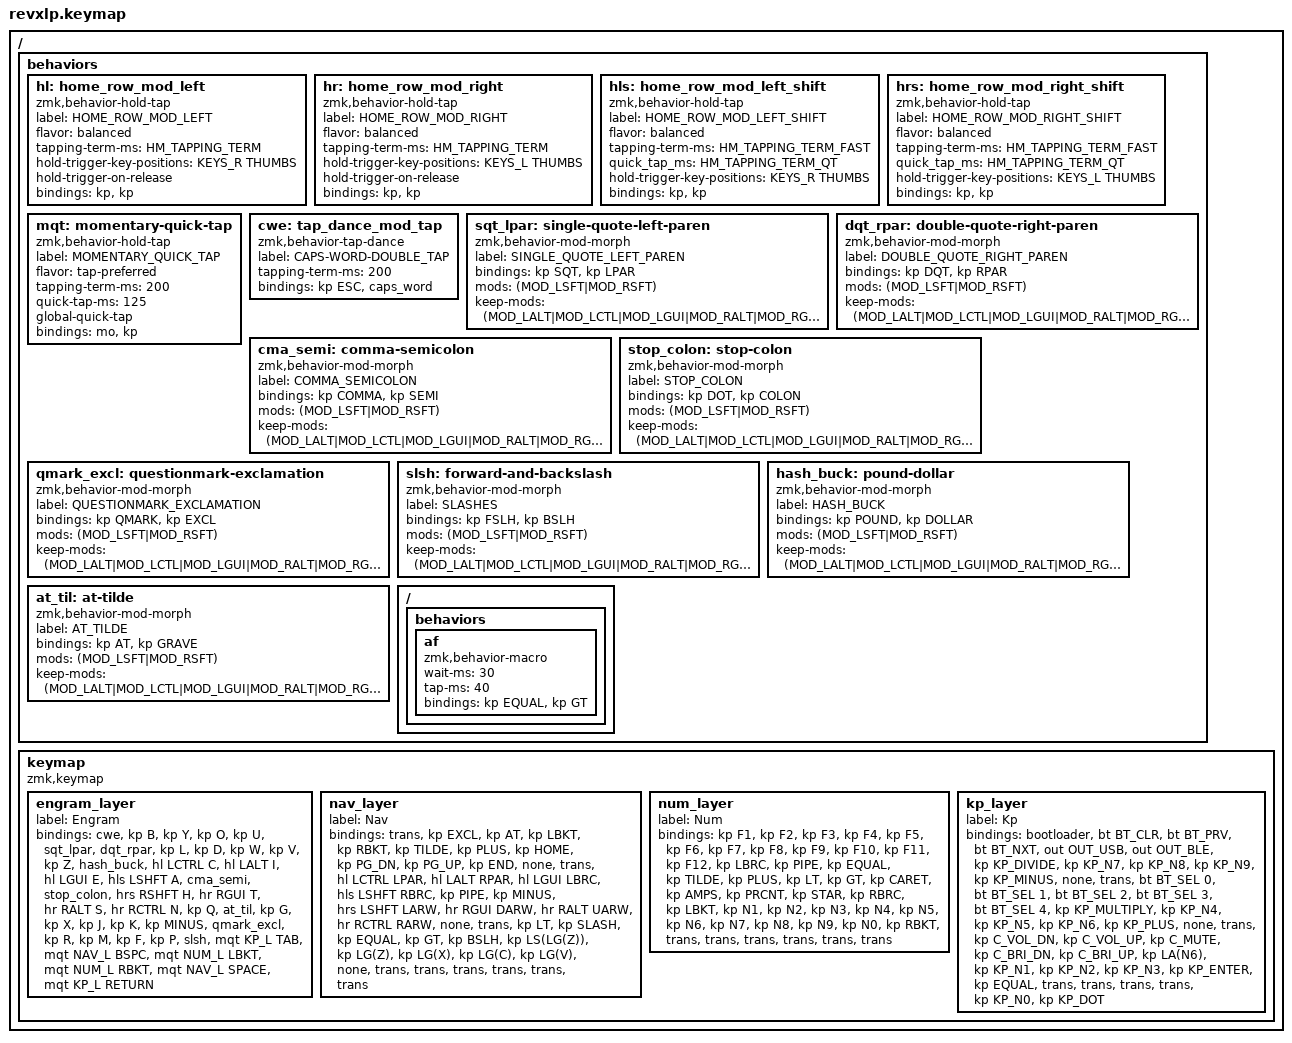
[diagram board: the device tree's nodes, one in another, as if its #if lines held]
/*
* Copyright (c) 2020 The ZMK Contributors
*
* SPDX-License-Identifier: MIT
*/

#include <behaviors.dtsi>
#include <dt-bindings/zmk/keys.h>
#include <dt-bindings/zmk/bt.h>
#include <dt-bindings/zmk/backlight.h>
#include <dt-bindings/zmk/outputs.h>

#define NAV_L 1
#define NUM_L 2
#define KP_L 3

#define KEYS_L 0 1 2 3 4  5  12 13 14 15 16 17 24 25 26 27 28 29// left-hand keys
#define KEYS_R 6 7 8 9 10 11 18 19 20 21 22 23 30 31 32 33 34 35// right-hand keys
#define THUMBS 36 37 38 39 40 41

#define HM_TAPPING_TERM 1000
#define HM_TAPPING_TERM_FAST 200
#define HM_TAPPING_TERM_QT 175

/ {
	behaviors {
		
		hl: home_row_mod_left {
			compatible = "zmk,behavior-hold-tap";
			label = "HOME_ROW_MOD_LEFT";
			#binding-cells = <2>;
			flavor = "balanced";
			tapping-term-ms = <HM_TAPPING_TERM>;
			hold-trigger-key-positions = < KEYS_R THUMBS >;
			hold-trigger-on-release;
			bindings = <&kp>, <&kp>;
		};
		
		hr: home_row_mod_right {
			compatible = "zmk,behavior-hold-tap";
			label = "HOME_ROW_MOD_RIGHT";
			#binding-cells = <2>;
			flavor = "balanced";
			tapping-term-ms = <HM_TAPPING_TERM>;
			hold-trigger-key-positions = < KEYS_L THUMBS >;
			hold-trigger-on-release;
			bindings = <&kp>, <&kp>;
		};
		
		hls: home_row_mod_left_shift {
			compatible = "zmk,behavior-hold-tap";
			label = "HOME_ROW_MOD_LEFT_SHIFT";
			#binding-cells = <2>;
			flavor = "balanced";
			tapping-term-ms = <HM_TAPPING_TERM_FAST>;
			quick_tap_ms = <HM_TAPPING_TERM_QT>;
			hold-trigger-key-positions = < KEYS_R THUMBS >;
			bindings = <&kp>, <&kp>;
		};
		
		hrs: home_row_mod_right_shift {
			compatible = "zmk,behavior-hold-tap";
			label = "HOME_ROW_MOD_RIGHT_SHIFT";
			#binding-cells = <2>;
			flavor = "balanced";
			tapping-term-ms = <HM_TAPPING_TERM_FAST>;
			quick_tap_ms = <HM_TAPPING_TERM_QT>;
			hold-trigger-key-positions = < KEYS_L THUMBS >;
			bindings = <&kp>, <&kp>;
		};
		
		mqt: momentary-quick-tap {
			compatible = "zmk,behavior-hold-tap";
			label = "MOMENTARY_QUICK_TAP";
			#binding-cells = <2>;
			flavor = "tap-preferred";
			tapping-term-ms = <200>;
			quick-tap-ms = <125>;
			global-quick-tap;
			bindings = <&mo>, <&kp>;
		};
		
		cwe: tap_dance_mod_tap {
			compatible = "zmk,behavior-tap-dance";
			label = "CAPS-WORD-DOUBLE_TAP";
			#binding-cells = <0>;
			tapping-term-ms = <200>;
			bindings = <&kp ESC>, <&caps_word>;
		};
		
		sqt_lpar: single-quote-left-paren {
			compatible = "zmk,behavior-mod-morph";
			label = "SINGLE_QUOTE_LEFT_PAREN";
			#binding-cells = <0>;
			bindings = <&kp SQT>, <&kp LPAR>;
			mods = <(MOD_LSFT|MOD_RSFT)>;
			keep-mods = <(MOD_LALT|MOD_LCTL|MOD_LGUI|MOD_RALT|MOD_RGUI|MOD_RCTL)>;
		};
		
		dqt_rpar: double-quote-right-paren {
			compatible = "zmk,behavior-mod-morph";
			label = "DOUBLE_QUOTE_RIGHT_PAREN";
			#binding-cells = <0>;
			bindings = <&kp DQT>, <&kp RPAR>;
			mods = <(MOD_LSFT|MOD_RSFT)>;
			keep-mods = <(MOD_LALT|MOD_LCTL|MOD_LGUI|MOD_RALT|MOD_RGUI|MOD_RCTL)>;
		};
		
		cma_semi: comma-semicolon {
			compatible = "zmk,behavior-mod-morph";
			label = "COMMA_SEMICOLON";
			#binding-cells = <0>;
			bindings = <&kp COMMA>, <&kp SEMI>;
			mods = <(MOD_LSFT|MOD_RSFT)>;
			keep-mods = <(MOD_LALT|MOD_LCTL|MOD_LGUI|MOD_RALT|MOD_RGUI|MOD_RCTL)>;
		};
		
		stop_colon: stop-colon {
			compatible = "zmk,behavior-mod-morph";
			label = "STOP_COLON";
			#binding-cells = <0>;
			bindings = <&kp DOT>, <&kp COLON>;
			mods = <(MOD_LSFT|MOD_RSFT)>;
			keep-mods = <(MOD_LALT|MOD_LCTL|MOD_LGUI|MOD_RALT|MOD_RGUI|MOD_RCTL)>;
		};
		
		qmark_excl: questionmark-exclamation {
			compatible = "zmk,behavior-mod-morph";
			label = "QUESTIONMARK_EXCLAMATION";
			#binding-cells = <0>;
			bindings = <&kp QMARK>, <&kp EXCL>;
			mods = <(MOD_LSFT|MOD_RSFT)>;
			keep-mods = <(MOD_LALT|MOD_LCTL|MOD_LGUI|MOD_RALT|MOD_RGUI|MOD_RCTL)>;
		};
		
		slsh: forward-and-backslash {
			compatible = "zmk,behavior-mod-morph";
			label = "SLASHES";
			#binding-cells = <0>;
			bindings = <&kp FSLH>, <&kp BSLH>;
			mods = <(MOD_LSFT|MOD_RSFT)>;
			keep-mods = <(MOD_LALT|MOD_LCTL|MOD_LGUI|MOD_RALT|MOD_RGUI|MOD_RCTL)>;
		};
		
		hash_buck: pound-dollar {
			compatible = "zmk,behavior-mod-morph";
			label = "HASH_BUCK";
			#binding-cells = <0>;
			bindings = <&kp POUND>, <&kp DOLLAR>;
			mods = <(MOD_LSFT|MOD_RSFT)>;
			keep-mods = <(MOD_LALT|MOD_LCTL|MOD_LGUI|MOD_RALT|MOD_RGUI|MOD_RCTL)>;
		};
		
		at_til: at-tilde {
			compatible = "zmk,behavior-mod-morph";
			label = "AT_TILDE";
			#binding-cells = <0>;
			bindings = <&kp AT>, <&kp GRAVE>;
			mods = <(MOD_LSFT|MOD_RSFT)>;
			keep-mods = <(MOD_LALT|MOD_LCTL|MOD_LGUI|MOD_RALT|MOD_RGUI|MOD_RCTL)>;
		};
		
		ZMK_MACRO(af,
		wait-ms = <30>;
		tap-ms = <40>;
		bindings = <&kp EQUAL  &kp GT>;
		)
		
	};
	
	
	keymap {
		compatible = "zmk,keymap";
		
    #if LAYOUT == ENGRAM
		engram_layer {
			label = "Engram";
			bindings = <
			&cwe         &kp B        &kp Y       &kp O       &kp U          &sqt_lpar   &dqt_rpar       &kp L          &kp D       &kp W       &kp V         &kp Z
			&hash_buck   &hl LCTRL C  &hl LALT I  &hl LGUI E &hls LSHFT A   &cma_semi   &stop_colon     &hrs RSHFT H   &hr RGUI T &hr RALT S &hr RCTRL N  &kp Q
			&at_til      &kp G        &kp X       &kp J       &kp K          &kp MINUS   &qmark_excl     &kp R          &kp M       &kp F       &kp P         &slsh
			&mqt KP_L TAB &mqt NAV_L BSPC  &mqt NUM_L LBKT  &mqt NUM_L RBKT &mqt NAV_L SPACE      &mqt KP_L RETURN
			>;
		};
		#elif LAYOUT == ENGRAMMER
		engrammer_layer {
			label = "Engram";
			bindings = <
			&kp GRAVE   &kp B        &kp Y       &kp O       &kp U          &kp SQT   &kp SEMI       &kp L          &kp D       &kp W       &kp V         &kp Z
			&cwe        &hl LCTRL C  &hl LALT I  &hl LGUI E  &hls LSHFT A   &kp COMMA   &kp DOT  &hrs LSHFT H   &hr RGUI T &hr RALT S &hr RCTRL N  &kp Q
			&kp EQUAL   &kp G        &kp X       &kp J       &kp K          &kp MINUS   &kp SLASH     &kp R          &kp M       &kp F       &kp P         &kp BSLH
			&mqt KP_L TAB &mqt NAV_L BSPC  &mqt NUM_L LBKT  &mqt NUM_L RBKT &mqt NAV_L SPACE      &mqt KP_L RETURN
			>;
		};
		#elif LAYOUT == QWERTY_FLIP
		qwerty_flip_layer {
			bindings = <
			&kp GRAVE &kp Q          &kp W        &kp D        &kp F          &kp G       &kp Y &kp J          &kp K        &kp L        &kp SEMI      &kp BSLH
			&cwe      &hl LCTRL A  &hl LALT S &hl LGUI E &hls LSHFT R &kp T       &kp H &hrs RSHFT U &hr RGUI I &hr RALT O &hr RCTRL P &kp SQT
			&kp MINUS &kp Z          &kp X        &kp C        &kp V          &kp B       &kp N &kp M          &kp COMMA    &kp DOT      &kp SLASH     &kp EQUAL
			&mqt KP_L TAB &mqt NAV_L BSPC  &mqt NUM_L LBKT  &mqt NUM_L RBKT &mqt NAV_L SPACE      &mqt KP_L RETURN
			>;
		};
    #else
		qwerty_layer {
			bindings = <
			&kp GRAVE &kp Q       &kp W      &kp E       &kp R        &kp T &kp Y &kp U        &kp I      &kp O      &kp P          &kp EQUAL
			&cwe      &hl LCTRL A &hl LALT S &hl LGUI D  &hls LSHFT F &kp G &kp H &hrs RSHFT J &hr RGUI K &hr RALT L &hr RCTRL SEMI &kp SQT
			&kp MINUS &kp Z       &kp X      &kp C       &kp V        &kp B &kp N &kp M        &kp COMMA  &kp DOT    &kp SLASH      &kp BSLH
			&mqt KP_L TAB &mqt NAV_L BSPC  &mqt NUM_L LBKT  &mqt NUM_L RBKT &mqt NAV_L SPACE      &mqt KP_L RETURN
			>;
		};
    #endif
		
		
		// ;; I used #(sft /) to release the shift from rolls with <
		// (deflayer navigation
		//   _    _    _    _    _    _    _    _    _    _    _    _    _    _
		//   _    !    @    [    ]    _    _    home pgdn pgup end  _    _    _
		//   _ @clp @arp @mlb @srb  @af    _    @sl  @md  @au  @cr  _    _
		//   < #(sft /) =   >    _    _    M-S-z M-z M-x  M-c  M-v  _    _
		//   _    _    _    _              _              _    _    _    _    _
		// )
		
		
		nav_layer {
			label = "Nav";
			bindings = <
			&trans   &kp EXCL   &kp AT     &kp LBKT    &kp RBKT         &kp TILDE       &kp PLUS         &kp  HOME       &kp PG_DN      &kp PG_UP   &kp END    &none
			&trans   &hl LCTRL LPAR &hl LALT RPAR &hl LGUI LBRC &hls LSHFT RBRC  &kp PIPE    &kp MINUS      &hrs LSHFT LARW   &hr RGUI DARW &hr RALT UARW &hr RCTRL RARW  &none
			&trans   &kp LT     &kp SLASH     &kp EQUAL      &kp GT             &kp BSLH         &kp LS(LG(Z))        &kp LG(Z)      &kp LG(X)   &kp LG(C)  &kp LG(V)     &none
			&trans       &trans             &trans         &trans      &trans    &trans
			>;
		};
		
    #if LAYOUT == ENGRAM
		num_layer {
			label = "Num";
			bindings = <
			&kp F1       &kp F2      &kp F3      &kp F4          &kp F5       &kp F6        &kp F7         &kp F8    &kp F9     &kp F10     &kp F11    &kp F12
			&kp LBRC     &kp PIPE    &kp EQUAL   &kp TILDE      &kp PLUS      &kp LT        &kp GT     &kp CARET     &kp AMPS   &kp PRCNT   &kp STAR   &kp RBRC
			&kp LBKT     &kp N1      &kp N2      &kp N3          &kp N4       &kp N5        &kp N6     &kp N7        &kp N8     &kp N9      &kp N0     &kp RBKT
			&trans   &trans          &trans        &trans       &trans &trans
			>;
		};
    #else
		num_layer {
			label = "Num";
			bindings = <
			&kp F1       &kp F2      &kp F3      &kp F4          &kp F5       &kp F6        &kp F7         &kp F8    &kp F9     &kp F10     &kp F11    &kp F12
			&kp LBRC     &kp EXCL    &kp AT   &kp POUND      &kp DOLLAR      &kp PERCENT    &kp CARET     &kp AMPS  &kp ASTRK   &kp LPAR   &kp RPAR   &kp RBRC
			&kp LBKT     &kp N1      &kp N2      &kp N3         &kp N4        &kp N5        &kp N6     &kp N7        &kp N8     &kp N9      &kp N0     &kp RBKT
			&trans   &trans          &trans        &trans        &trans &trans
			>;
		};
    #endif
		
		kp_layer {
			label = "Kp";
			bindings = <
			&bootloader    &bt BT_CLR   &bt BT_PRV   &bt BT_NXT      &out OUT_USB         &out OUT_BLE   &kp KP_DIVIDE     &kp  KP_N7  &kp KP_N8   &kp KP_N9   &kp KP_MINUS      &none
			&trans         &bt BT_SEL 0 &bt BT_SEL 1 &bt BT_SEL 2    &bt BT_SEL 3         &bt BT_SEL 4 &kp KP_MULTIPLY     &kp KP_N4    &kp KP_N5    &kp KP_N6   &kp KP_PLUS      &none
			&trans         &kp C_VOL_DN &kp C_VOL_UP &kp C_MUTE          &kp C_BRI_DN      &kp C_BRI_UP         &kp LA(N6)     &kp KP_N1   &kp KP_N2   &kp KP_N3  &kp KP_ENTER    &kp EQUAL
			&trans       &trans         &trans         &trans      &kp KP_N0    &kp KP_DOT
			>;
		};
	};
};
